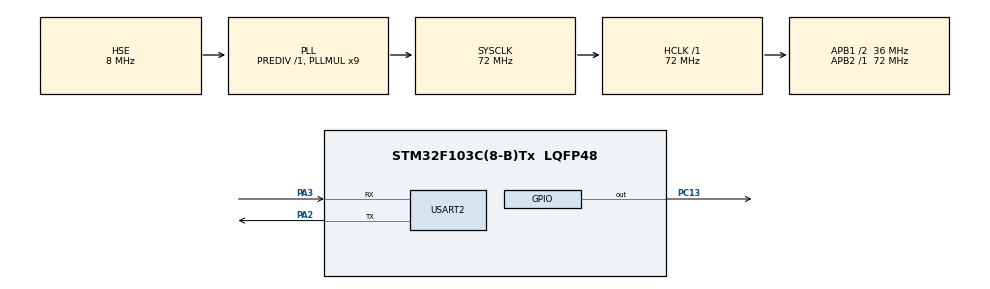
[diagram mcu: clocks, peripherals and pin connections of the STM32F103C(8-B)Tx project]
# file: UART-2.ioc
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Mcu.Family=STM32F1
Mcu.Name=STM32F103C(8-B)Tx
Mcu.Package=LQFP48
NVIC.PriorityGroup=NVIC_PRIORITYGROUP_4
PA13.Mode=Serial_Wire
PA13.Signal=SYS_JTMS-SWDIO
PA14.Mode=Serial_Wire
PA14.Signal=SYS_JTCK-SWCLK
PA2.Mode=Asynchronous
PA2.Signal=USART2_TX
PA3.Mode=Asynchronous
PA3.Signal=USART2_RX
PC13-TAMPER-RTC.Signal=GPIO_Output
PD0-OSC_IN.Mode=HSE-External-Oscillator
PD0-OSC_IN.Signal=RCC_OSC_IN
PD1-OSC_OUT.Mode=HSE-External-Oscillator
PD1-OSC_OUT.Signal=RCC_OSC_OUT
ProjectManager.HeapSize=0x200
ProjectManager.StackSize=0x400
ProjectManager.TargetToolchain=MDK-ARM V5.32
RCC.AHBFreq_Value=72000000
RCC.APB1CLKDivider=RCC_HCLK_DIV2
RCC.APB1Freq_Value=36000000
RCC.APB1TimFreq_Value=72000000
RCC.APB2Freq_Value=72000000
RCC.APB2TimFreq_Value=72000000
RCC.HCLKFreq_Value=72000000
RCC.PLLMUL=RCC_PLL_MUL9
RCC.PLLSourceVirtual=RCC_PLLSOURCE_HSE
RCC.SYSCLKFreq_VALUE=72000000
RCC.SYSCLKSource=RCC_SYSCLKSOURCE_PLLCLK
RCC.USBFreq_Value=72000000
USART2.VirtualMode=VM_ASYNC
board=custom

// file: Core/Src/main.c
/* USER CODE BEGIN Header */
/**
  ******************************************************************************
  * @file           : main.c
  * @brief          : Main program body
  ******************************************************************************
  * @attention
  *
  * Copyright (c) 2026 STMicroelectronics.
  * All rights reserved.
  *
  * This software is licensed under terms that can be found in the LICENSE file
  * in the root directory of this software component.
  * If no LICENSE file comes with this software, it is provided AS-IS.
  *
  ******************************************************************************
  */
/* USER CODE END Header */
#include "main.h"
#include <string.h>
#define CMD_MAX_LEN 15

UART_HandleTypeDef huart2;

void SystemClock_Config(void);
static void MX_GPIO_Init(void);
static void MX_USART2_UART_Init(void);

int main(void)
{
	char command_array[CMD_MAX_LEN];
	uint8_t array_index = 0;

  /* MCU Configuration--------------------------------------------------------*/

  /* Reset of all peripherals, Initializes the Flash interface and the Systick. */
  HAL_Init();

  /* Configure the system clock */
  SystemClock_Config();

  /* Initialize all configured peripherals */
  MX_GPIO_Init();
  MX_USART2_UART_Init();

  /* Infinite loop */
  /* USER CODE BEGIN WHILE */
  while (1)
  {
		char incoming_char;
    if (HAL_UART_Receive(&huart2, (uint8_t *)&incoming_char, 1, HAL_MAX_DELAY) == HAL_OK)
    {
        HAL_UART_Transmit(&huart2, (uint8_t *)&incoming_char, 1, 100);
        if (incoming_char == '\r' || incoming_char == '\n')
        {
            if (array_index > 0)
            {
                command_array[array_index] = '\0';
                if (strcmp(command_array, "LED OFF") == 0)
                {
                    HAL_GPIO_WritePin(GPIOC, GPIO_PIN_13, GPIO_PIN_SET);
                    char msg[] = "\r\nLED turned OFF\r\n";
                    HAL_UART_Transmit(&huart2, (uint8_t *)msg, strlen(msg), 100);
                }
                else if (strcmp(command_array, "LED ON") == 0)
                {
                    HAL_GPIO_WritePin(GPIOC, GPIO_PIN_13, GPIO_PIN_RESET);
                    char msg[] = "\r\nLED turned ON\r\n";
                    HAL_UART_Transmit(&huart2, (uint8_t *)msg, strlen(msg), 100);
                }
                else if (strcmp(command_array, "LED TOGGLE") == 0)
                {
                    HAL_GPIO_TogglePin(GPIOC, GPIO_PIN_13);
                    char msg[] = "\r\nLED toggled\r\n";
                    HAL_UART_Transmit(&huart2, (uint8_t *)msg, strlen(msg), 100);
                }

                array_index = 0;
            }
        }
        else
        {
            if (array_index < (CMD_MAX_LEN - 1))
            {
                command_array[array_index] = incoming_char;
                array_index++;
            }
            else
            {
                array_index = 0;
            }
        }
    }
    /* USER CODE END WHILE */

  }
}

void SystemClock_Config(void)
{
  RCC_OscInitTypeDef RCC_OscInitStruct = {0};
  RCC_ClkInitTypeDef RCC_ClkInitStruct = {0};

  /** Initializes the RCC Oscillators according to the specified parameters
  * in the RCC_OscInitTypeDef structure.
  */
  RCC_OscInitStruct.OscillatorType = RCC_OSCILLATORTYPE_HSE;
  RCC_OscInitStruct.HSEState = RCC_HSE_ON;
  RCC_OscInitStruct.HSEPredivValue = RCC_HSE_PREDIV_DIV1;
  RCC_OscInitStruct.HSIState = RCC_HSI_ON;
  RCC_OscInitStruct.PLL.PLLState = RCC_PLL_ON;
  RCC_OscInitStruct.PLL.PLLSource = RCC_PLLSOURCE_HSE;
  RCC_OscInitStruct.PLL.PLLMUL = RCC_PLL_MUL9;
  if (HAL_RCC_OscConfig(&RCC_OscInitStruct) != HAL_OK)
  {
    Error_Handler();
  }

  /** Initializes the CPU, AHB and APB buses clocks
  */
  RCC_ClkInitStruct.ClockType = RCC_CLOCKTYPE_HCLK|RCC_CLOCKTYPE_SYSCLK
                              |RCC_CLOCKTYPE_PCLK1|RCC_CLOCKTYPE_PCLK2;
  RCC_ClkInitStruct.SYSCLKSource = RCC_SYSCLKSOURCE_PLLCLK;
  RCC_ClkInitStruct.AHBCLKDivider = RCC_SYSCLK_DIV1;
  RCC_ClkInitStruct.APB1CLKDivider = RCC_HCLK_DIV2;
  RCC_ClkInitStruct.APB2CLKDivider = RCC_HCLK_DIV1;

  if (HAL_RCC_ClockConfig(&RCC_ClkInitStruct, FLASH_LATENCY_2) != HAL_OK)
  {
    Error_Handler();
  }
}

static void MX_USART2_UART_Init(void)
{

  huart2.Instance = USART2;
  huart2.Init.BaudRate = 115200;
  huart2.Init.WordLength = UART_WORDLENGTH_8B;
  huart2.Init.StopBits = UART_STOPBITS_1;
  huart2.Init.Parity = UART_PARITY_NONE;
  huart2.Init.Mode = UART_MODE_TX_RX;
  huart2.Init.HwFlowCtl = UART_HWCONTROL_NONE;
  huart2.Init.OverSampling = UART_OVERSAMPLING_16;
  if (HAL_UART_Init(&huart2) != HAL_OK)
  {
    Error_Handler();
  }

}

static void MX_GPIO_Init(void)
{
  GPIO_InitTypeDef GPIO_InitStruct = {0};

  /* GPIO Ports Clock Enable */
  __HAL_RCC_GPIOC_CLK_ENABLE();
  __HAL_RCC_GPIOD_CLK_ENABLE();
  __HAL_RCC_GPIOA_CLK_ENABLE();

  /*Configure GPIO pin Output Level */
  HAL_GPIO_WritePin(GPIOC, GPIO_PIN_13, GPIO_PIN_RESET);

  /*Configure GPIO pin : PC13 */
  GPIO_InitStruct.Pin = GPIO_PIN_13;
  GPIO_InitStruct.Mode = GPIO_MODE_OUTPUT_PP;
  GPIO_InitStruct.Pull = GPIO_NOPULL;
  GPIO_InitStruct.Speed = GPIO_SPEED_FREQ_LOW;
  HAL_GPIO_Init(GPIOC, &GPIO_InitStruct);

}

void Error_Handler(void)
{
  __disable_irq();
  while (1)
  {
  }
}
